// intentionally incorrect — Motorola (big-endian) start bit computed with
// Intel (little-endian) bit numbering. Sawtooth position of the MSB of byte 0
// is 0, not 7. This DBC loads fine in cantools and "decodes", but
// WheelSpeedFL comes out as 112.64 km/h instead of 6.0 km/h on the fixture
// frame — a silent, plausible-but-wrong result.
VERSION ""

NS_ :

BS_:

BU_: ECM VCU

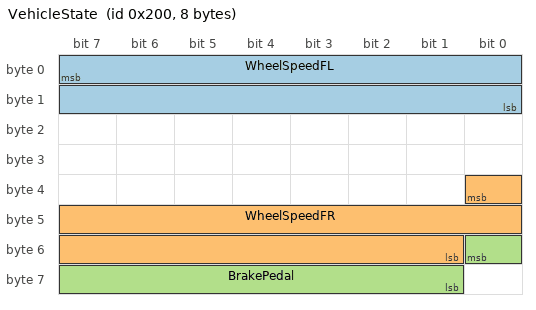
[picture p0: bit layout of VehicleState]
BO_ 512 VehicleState: 8 VCU
 SG_ WheelSpeedFL : 7|16@0+ (0.01,0) [0|655] "km/h"  ECM
 SG_ WheelSpeedFR : 32|16@0+ (0.01,0) [0|655] "km/h"  ECM
 SG_ BrakePedal : 48|8@0+ (0.5,0) [0|100] "%"  ECM
